# AM13E230x register map
Vendor: Texas Instruments; File version: Revised: 2025-12-26 17:30:06
CPU: CM33 r0p0, little endian, MPU, FPU, 4 interrupt priority bits
Registers are 32-bit, read-write, reset 0x0 unless marked. A register's access mark holds for its fields unless they carry their own. Offsets are from the block's base; [hi:lo] are bit positions; lines under a group give offsets from that group; {n}, {i} and the like mark numbered series; 'fields as' and 'values as' point back to an identical list; <NAME> marks a mode.

## UC0_I2CC — PERIPHERALREGION
Base 0x40608000
Same registers: UC1_I2CC 0x40609000, UC2_I2CC 0x4060A000, UC3_I2CC 0x40648000, UC4_I2CC 0x40649000, UC5_I2CC 0x4064A000
0x00 CLKDIV — Clock Divider
  [2:0] RATIO — Selects divide ratio of module clock Division factor 0 : DIV_BY_1 1 : DIV_BY_2 .... 63: DIV_BY_64
    0=DIV_BY_1 (Do not divide clock source); {v}=DIV_BY_{v+1} (Divide clock source by {v+1}) (v=1..7)
0x08 CLKSEL — Clock Select for Ultra Low Power peripherals
  [3] BUSCLK_SEL — Selects BUS CLK as clock source if enabled
    0=DISABLE (Does not select this clock as a source); 1=ENABLE (Select this clock as a source)
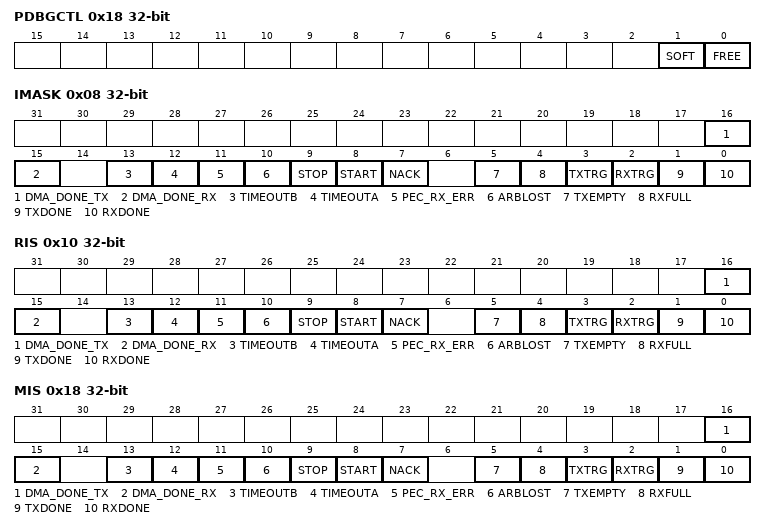
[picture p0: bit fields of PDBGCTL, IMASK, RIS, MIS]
0x18 PDBGCTL — Peripheral Debug Control
  [1] SOFT — Soft halt boundary control. This function is only available, if [FREE] is set to 'STOP'
    0=DEPRECATED (Not supported); 1=DELAYED (The peripheral blocks the debug freeze until it has reached a boundary where it can resume without corruption)
  [0] FREE — Free run control
    0=STOP (The peripheral freezes functionality while the Core Halted input is asserted and resumes when it is deasserted.); 1=RUN (The peripheral ignores the state of the Core Halted input)
0x20 CPU_INT group
  0x00 IIDX ro — Interrupt index
    [7:0] STAT — I2C Module Interrupt Vector Value. This register provides the highes priority interrupt index. A read clears the corresponding interrupt flag in RIS and MISC. 15h-1Fh = Reserved
      0=NO_INTR (No interrupt pending); 1=RXDONEFG (Data received); 2=TXDONEFG (data transmitted); 3=RXTRG (Receive Trigger); 4=TXTRG (Transmit Trigger); 5=RXFULL (RX FIFO FULL Event/interrupt pending); 6=TXEMPTY (Transmit FIFO/Buffer Empty Event/interrupt pending); 8=NACKFG (Address/Data NACK); 9=STARTFG (Start Event); 10=STOPFG (Stop Event); 11=ARBLOSTFG (Arbitration Lost); 12=PEC_RX_ERR (PEC Receive Error Event); 13=TIMEOUTA (Timeout A Event); 14=TIMEOUTB (Timeout B Event); 16=DMA_DONE_RX (DMA DONE on Channel RX); 17=DMA_DONE_TX (DMA DONE on Channel TX); 19=DMA_PREIRQ_RX (DMA PRE IRQ INTERRUPT); 20=DMA_PREIRQ_TX (DMA PRE IRQ INTERRUPT)
  0x08 IMASK — Interrupt mask
    [16] DMA_DONE_TX — DMA Done on Event Channel TX
    [15] DMA_DONE_RX — DMA Done on Event Channel RX
    [13] TIMEOUTB — Timeout B Interrupt
    [12] TIMEOUTA — TIMEOUTA interrupt
    [11] PEC_RX_ERR — RX Pec Error Interrupt
    [10] ARBLOST — Arbitration Lost interrupt
    [9] STOP — STOP interrupt
    [8] START — START interrupt
    [7] NACK — NACK interrupt
    [5] TXEMPTY — Interrupt Mask for Transmit FIFO Empty
    [4] RXFULL — RXFIFO full event
    [3] TXTRG — Transmit Trigger
    [2] RXTRG — Receive FIFO Trigger
    [1] TXDONE — Transmit Transaction completed Interrupt
    [0] RXDONE — RXDONE interrupt
  0x10 RIS ro — Raw interrupt status
    [16] DMA_DONE_TX — DMA Done on Event Channel TX
    [15] DMA_DONE_RX — DMA Done on Event Channel RX
    [13] TIMEOUTB — Timeout B Interrupt
    [12] TIMEOUTA — Timeout A Interrupt
    [11] PEC_RX_ERR — Receive PEC Error Interrupt: set when the calculated PEC does not match received PEC
    [10] ARBLOST — Arbitration Lost Interrupt: in multi-controller systems, when this controller loses out during arbitration
    [9] STOP — STOP Detection Interrupt
    [8] START — START Detection Interrupt
    [7] NACK — Address/Data NACK Interrupt: set when address or data nack is received
    [5] TXEMPTY — Transmit FIFO Empty interrupt mask
    [4] RXFULL — RXFIFO full event
    [3] TXTRG — Transmit Trigger
    [2] RXTRG — Receive Trigger
    [1] TXDONE — Transmit Done Interrupt: TXDONE interrupt is raised when a burst length completes Or, in case of quick command, when a quick command with R/Wn bit set to '0'
    [0] RXDONE — Receive Done Interrupt: RXDONE interrupt is raised when a burst length completes Or, in case of quick command, when a quick command with R/Wn bit set to '1'
  0x18 MIS ro — Masked interrupt status
    [16] DMA_DONE_TX — DMA Done on Event Channel TX
    [15] DMA_DONE_RX — DMA Done on Event Channel RX
    [13] TIMEOUTB — Timeout B Interrupt
    [12] TIMEOUTA — Timeout A Interrupt
    [11] PEC_RX_ERR — RX Pec Error Interrupt
    [10] ARBLOST — Arbitration Lost Interrupt
    [9] STOP — STOP Detection Interrupt
    [8] START — START Detection Interrupt
    [7] NACK — Address/Data NACK Interrupt
    [5] TXEMPTY — Transmit FIFO Empty interrupt mask
    [4] RXFULL — RXFIFO full
    [3] TXTRG — Transmit Trigger
    [2] RXTRG — Receive FIFO Trigger
    [1] TXDONE — Transmit Transaction completed Interrupt
    [0] RXDONE — Receive Data Interrupt
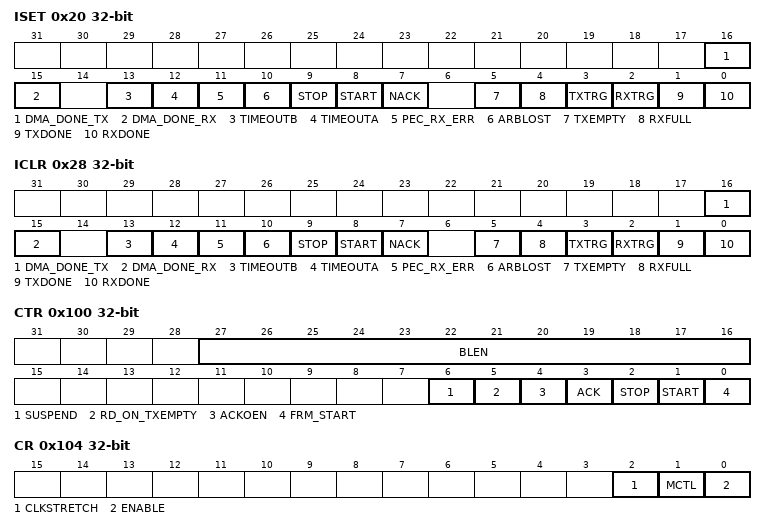
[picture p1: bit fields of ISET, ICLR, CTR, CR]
  0x20 ISET wo — Interrupt set
    [16] DMA_DONE_TX — DMA Done on Event Channel TX
    [15] DMA_DONE_RX — DMA Done on Event Channel RX
    [13] TIMEOUTB — Timeout B Interrupt
    [12] TIMEOUTA — Timeout A interrupt
    [11] PEC_RX_ERR — RX Pec Error Interrupt
    [10] ARBLOST — Arbitration Lost Interrupt
    [9] STOP — STOP Detection Interrupt
    [8] START — START Detection Interrupt
    [7] NACK — Address/Data NACK Interrupt
    [5] TXEMPTY — Transmit FIFO Empty interrupt mask
    [4] RXFULL — RXFIFO full event
    [3] TXTRG — Transmit FIFO Trigger
    [2] RXTRG — Receive FIFO Trigger
    [1] TXDONE — Transmit Transaction completed Interrupt
    [0] RXDONE — Receive Data Interrupt Signals that a byte has been received
  0x28 ICLR wo — Interrupt clear
    fields as CPU_INT.ISET
0x50 DMA_TRIG1 group
  0x08 IMASK — Interrupt mask
    [2] RXTRG — Receive FIFO Trigger
  0x10 RIS ro — Raw interrupt status
    [2] RXTRG — Receive Trigger
  0x18 MIS ro — Masked interrupt status
    [2] RXTRG — Receive FIFO Trigger
  0x20 ISET wo — Interrupt set
    [2] RXTRG — Receive FIFO Trigger
0x80 DMA_TRIG0 group
  0x08 IMASK — Interrupt mask
    [3] TXTRG — Transmit FIFO Trigger
  0x10 RIS ro — Raw interrupt status
    [3] TXTRG — Transmit FIFO Trigger
  0x18 MIS ro — Masked interrupt status
    [3] TXTRG — Transmit FIFO Trigger
  0x20 ISET wo — Interrupt set
    [3] TXTRG — Transmit FIFO Trigger
0xE4 INTCTL wo — Interrupt control register
  [0] INTEVAL — Writing a 1 to this field re-evaluates the interrupt sources.
    0=DISABLE (The interrupt or event line is disabled.); 1=EVAL (The interrupt or event line is in software mode. Software must clear the RIS.)
0x100 CTR — Control Register
  [27:16] BLEN — I2C transaction length
  [6] SUSPEND — Suspend external communication
    0=DISABLE (Functional mode resumed); 1=ENABLE (External communication suspended)
  [5] RD_ON_TXEMPTY — Read on TX Empty
    0=DISABLE (No special behavior); 1=ENABLE (When 1 the Controller will transmit all bytes from the TX FIFO before continuing with the programmed Burst Run Read. If the DIR is not set to Read in the MSA then this bit is ignored. The Start must be set in the MCTR for proper I2C protocol. The Controller will first send the Start Condition, I2C Address with R/W bit set to write, before sending the bytes in the TX FIFO. When the TX FIFO is empty, the I2C transaction will continue as programmed in MTCR and MSA without sending a Stop Condition. This is intended to be used to perform simple I2C command based reads transition that will complete after initiating them without having to get an interrupt to turn the bus around.)
  [4] ACKOEN — ACK overrride Enable
    0=DISABLE (No special behavior); 1=ENABLE (When 1 and the Controller is receiving data and the number of bytes indicated in MBLEN have been received, the state machine will generate an rxdone interrupt and wait at the start of the ACK for FW to indicate if an ACK or NACK should be sent. The ACK or NACK is selected by writing the MCTR register and setting ACK accordingly. The other fields in this register can also be written at this time to continue on with the transaction. If a NACK is sent the state machine will automatically send a Stop.)
  [3] ACK — Data Acknowledge Enable
    0=DISABLE (The last received data byte of a transaction is not acknowledged automatically .); 1=ENABLE (The last received data byte of a transaction is acknowledged automatically .)
  [2] STOP — Generate STOP
    0=DISABLE (The controller does not generate the STOP condition.); 1=ENABLE (The controller generates the STOP condition. See field decoding in Table: MCTR Field decoding.)
  [1] START — Generate START
    0=DISABLE (The controller does not generate the START condition.); 1=ENABLE (The controller generates the START or repeated START condition. See field decoding in Table: MCTR Field decoding.)
  [0] FRM_START — Start Transfer
    0=DISABLE (In standard mode, this encoding means the Controller is unable to transmit or receive data.); 1=ENABLE (The Controller is able to transmit or receive data. See field decoding in Table: MCTR Field decoding.)
0x104 CR — Configuration
  [2] CLKSTRETCH — Clock Stretching
    0=DISABLE (Disables the clock stretching detection. This can be disabled if no Target on the bus does support clock stretching, so that the maximum speed on the bus can be reached.); 1=ENABLE (Enables the clock stretching detection. Enabling the clock stretching ensures compliance to the I2C standard but could limit the speed due the clock stretching.)
  [1] MCTL — MultiController mode. In MultiController mode the SCL high time counts once the SCL line has been detected high. If this is not enabled the high time counts as soon as the SCL line has been set high by the I2C controller.
    0=DISABLE (Disable MultiController mode.); 1=ENABLE (Enable MultiController mode.)
  [0] ENABLE — Enable module. After this bit has been set, it should not be set again unless it has been cleared by writing a 0 or by a reset, otherwise transfer failures may occur.
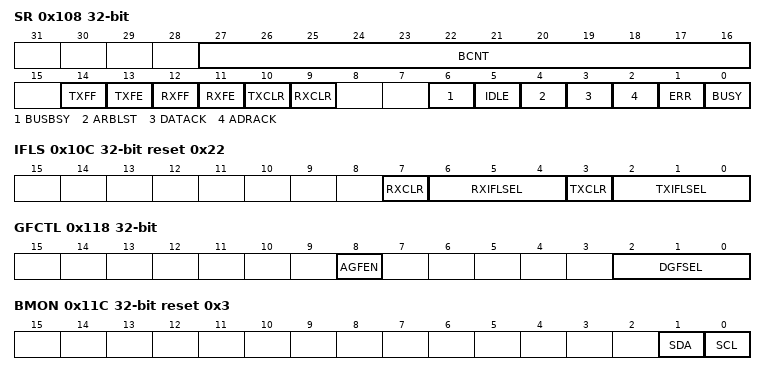
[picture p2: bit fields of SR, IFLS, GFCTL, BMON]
0x108 SR ro — Status Register
  [27:16] BCNT — transaction count
  [14] TXFF — Transmit FIFO Full The meaning of this bit depends on the state of the FEN bit in the CTL0 register.
  [13] TXFE — Transmit FIFO Empty The meaning of this bit depends on the state of the FEN bit in the CTL0 register.
  [12] RXFF — Receive FIFO Full The meaning of this bit depends on the state of the FEN bit in the CTL0 register.
  [11] RXFE — Receive FIFO Empty The meaning of this bit depends on the state of the FEN bit in the CTL0 register.
  [10] TXCLR — TX FIFO Clear Status
  [9] RXCLR — RX FIFO Clear Status
  [6] BUSBSY — I2C Bus is Busy Controller State Machine will wait until this bit to be cleared before starting a transaction. When first enabling the Controller in multi Controller environments, FW should wait for one I2C clock period after setting ACTIVE high before writing to the CTR register to start the transaction so that if SCL goes low it will trigger the BUSBSY.
  [5] IDLE — I2C Idle
  [4] ARBLST — Arbitration Lost
  [3] DATACK — Acknowledge Data
  [2] ADRACK — Acknowledge Address
  [1] ERR — Error The error can be from the Target address not being acknowledged or the transmit data not being acknowledged.
  [0] BUSY — FSM Busy The BUSY bit is set during an ongoing transaction, so is set during the transmit/receive of the amount of data set in MBLEN including START, RESTART, Address and STOP signal generation when required for the current transaction.
0x10C IFLS reset 0x22 — Interrupt FIFO Level Select Register
  [7] RXCLR — RX FIFO CLEAR
    0=DISABLE (Disable FIFO clear); 1=ENABLE (Enable FIFO Clear)
  [6:4] RXIFLSEL — FIFO Level Select for generating events (interrupt/dma). Note: for undefined settings the default configuration is used.
    1=LVL_1_4 (RX FIFO >= 1/4 full); 2=LVL_1_2 (RX FIFO >= 1/2 full (default)); 3=LVL_3_4 (RX FIFO >= 3/4 full); 4=LVL_NOT_EMPTY (Opposite of empty); 5=LVL_FULL (RX FIFO is full); 6=LVL_ALMOST_FULL (RX_FIFO >= (MAX_FIFO_LEN -1)); 7=LVL_ALMOST_EMPTY (RX_FIFO <= 1)
  [3] TXCLR — RX FIFO Flush
    0=DISABLE (Disable FIFO clear); 1=ENABLE (Enable FIFO Clear)
  [2:0] TXIFLSEL — FIFO Level Select for generating events (interrupt/dma). Note: for undefined settings the default configuration is used.
    1=LVL_3_4 (TX FIFO <= 3/4 empty); 2=LVL_1_2 (TX FIFO <= 1/2 empty (default)); 3=LVL_1_4 (TX FIFO <= 1/4 empty); 4=LVL_NOT_FULL (Opposite of full); 5=LVL_EMPTY (TX FIFO is empty); 6=LVL_ALMOST_EMPTY (TX FIFO <= 1); 7=LVL_ALMOST_FULL (TX_FIFO >= (MAX_FIFO_LEN -1))
0x110 TPR reset 0x1 — Timer Period
  [6:0] TPR — Timer Period This field is used in the equation to configure SCL_PERIOD : SCL_PERIOD = (1 + TPR ) * (SCL_LP + SCL_HP ) * INT_CLK_PRD where: SCL_PRD is the SCL line period (I2C clock). TPR is the Timer Period register value (range of 1 to 127). SCL_LP is the SCL Low period (fixed at 6). SCL_HP is the SCL High period (fixed at 4). CLK_PRD is the functional clock period in ns.
0x118 GFCTL — I2C Glitch Filter Control
  [8] AGFEN — Analog Glitch Suppression Enable
    0=DISABLE (Analog Glitch Filter disable); 1=ENABLE (Analog Glitch Filter enable)
  [2:0] DGFSEL — Glitch Suppression Pulse Width This field controls the pulse width select for glitch suppression on the SCL and SDA lines. The following values are the glitch suppression values in terms of functional clocks. (Core Domain only)
    0=DISABLED (Bypass); 1=CLK_1 (1 clock); 2=CLK_2 (2 clocks); 3=CLK_3 (3 clocks); 4=CLK_4 (4 clocks); 5=CLK_8 (8 clocks); 6=CLK_16 (16 clocks); 7=CLK_31 (31 clocks)
0x11C BMON ro reset 0x3 — Bus Monitor
  [1] SDA — I2C SDA Status
  [0] SCL — I2C SCL Status
0x120 TXDATA wo
  [7:0] DATA — Transmit Data This byte contains the data to be transferred during the next transaction.
0x124 RXDATA ro
  [7:0] DATA — Received Data. This field contains the last received data.
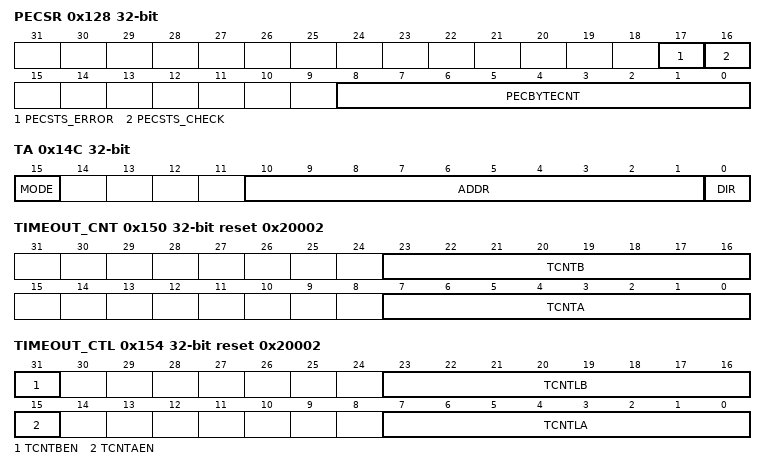
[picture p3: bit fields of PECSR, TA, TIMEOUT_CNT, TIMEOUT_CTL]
0x128 PECSR ro — PEC status register
  [17] PECSTS_ERROR — PEC Error Status
  [16] PECSTS_CHECK — PEC Check Status
  [8:0] PECBYTECNT — PEC Current Count
0x14C TA — Target Address Register
  [15] MODE — Addressing Mode
    0=7-bit addressing mode; 1=10-bit addressing mode
  [10:1] ADDR — Target Address
  [0] DIR — Receive/Send The DIR bit specifies if the next operation is a Receive (High) or Transmit (Low). 0h = Transmit 1h = Receive
    0=TRANSMIT (in transmit mode.); 1=RECEIVE (is in receive mode.)
0x150 TIMEOUT_CNT ro reset 0x20002 — I2C Timeout Count Register
  [23:16] TCNTB — Timeout Count B Current Count: This field contains the upper 8 bits of a 12-bit current counter for timeout counter B
  [7:0] TCNTA — Timeout Count A Current Count: This field contains the upper 8 bits of a 12-bit current counter for timeout counter A
0x154 TIMEOUT_CTL reset 0x20002 — I2C Timeout Count Control Register
  [31] TCNTBEN — Timeout Counter B Enable
    0=DISABLE (Disable Timeout Counter B); 1=ENABLE (Enable Timeout Counter B)
  [23:16] TCNTLB — Timeout Count B Load: Counter B is used for SCL High Detection. This field contains the upper 8 bits of a 12-bit pre-load value for the Timeout B count. NOTE: The value of CNTLB must be greater than 1h. Each count is equal to 1* clock period. For example, with 10MHz functional clock one timeout period will be equal to1*100ns.
  [15] TCNTAEN — Timeout Counter A Enable
    values as TCNTBEN
  [7:0] TCNTLA — Timeout counter A load value Counter A is used for SCL low detection. This field contains the upper 8 bits of a 12-bit pre-load value for the Timeout A count. NOTE: The value of CNTLA must be greater than 1h. Each count is equal to 520 times the timeout period of functional clock. For example, with 8MHz functional clock and a 100KHz operating I2C clock, one timeout period will be equal to (1 / 8MHz) * 520 or 65 us.
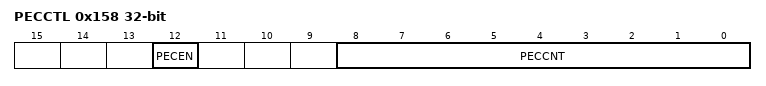
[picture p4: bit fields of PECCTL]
0x158 PECCTL — I2C PEC control register
  [12] PECEN — PEC Enable
    0=DISABLE (PEC is disabled); 1=ENABLE (PEC is enabled)
  [8:0] PECCNT — PEC Count
